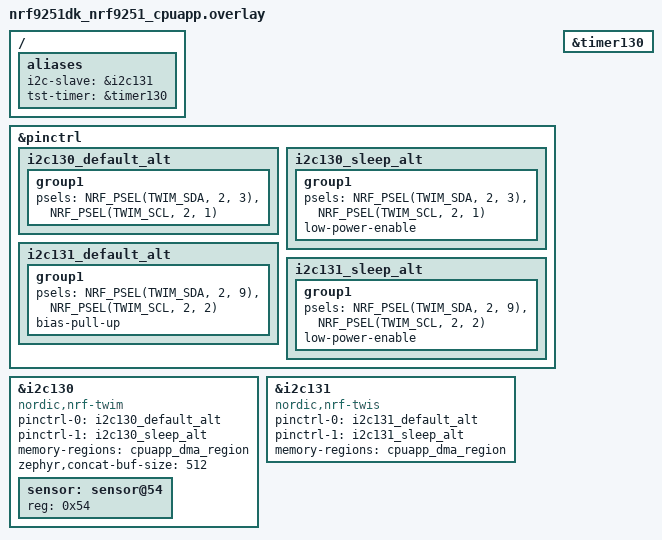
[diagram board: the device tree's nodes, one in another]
/* Test requires two loopbacks:
 * - P2.01 - P2.02,
 * - P2.03 - P2.09.
 */

/ {
	aliases {
		i2c-slave = &i2c131;
		tst-timer = &timer130;
	};
};

&pinctrl {
	i2c130_default_alt: i2c130_default_alt {
		group1 {
			psels = <NRF_PSEL(TWIM_SDA, 2, 3)>,
				<NRF_PSEL(TWIM_SCL, 2, 1)>;
		};
	};

	i2c130_sleep_alt: i2c130_sleep_alt {
		group1 {
			psels = <NRF_PSEL(TWIM_SDA, 2, 3)>,
				<NRF_PSEL(TWIM_SCL, 2, 1)>;
			low-power-enable;
		};
	};

	i2c131_default_alt: i2c131_default_alt {
		group1 {
			psels = <NRF_PSEL(TWIM_SDA, 2, 9)>,
				<NRF_PSEL(TWIM_SCL, 2, 2)>;
			bias-pull-up;
		};
	};

	i2c131_sleep_alt: i2c131_sleep_alt {
		group1 {
			psels = <NRF_PSEL(TWIM_SDA, 2, 9)>,
				<NRF_PSEL(TWIM_SCL, 2, 2)>;
			low-power-enable;
		};
	};
};

dut_twim: &i2c130 {
	compatible = "nordic,nrf-twim";
	status = "okay";
	pinctrl-0 = <&i2c130_default_alt>;
	pinctrl-1 = <&i2c130_sleep_alt>;
	pinctrl-names = "default", "sleep";
	memory-regions = <&cpuapp_dma_region>;
	zephyr,concat-buf-size = <512>;

	sensor: sensor@54 {
		reg = <0x54>;
	};
};

dut_twis: &i2c131 {
	compatible = "nordic,nrf-twis";
	status = "okay";
	pinctrl-0 = <&i2c131_default_alt>;
	pinctrl-1 = <&i2c131_sleep_alt>;
	pinctrl-names = "default", "sleep";
	memory-regions = <&cpuapp_dma_region>;
};

&timer130 {
	status = "okay";
};
